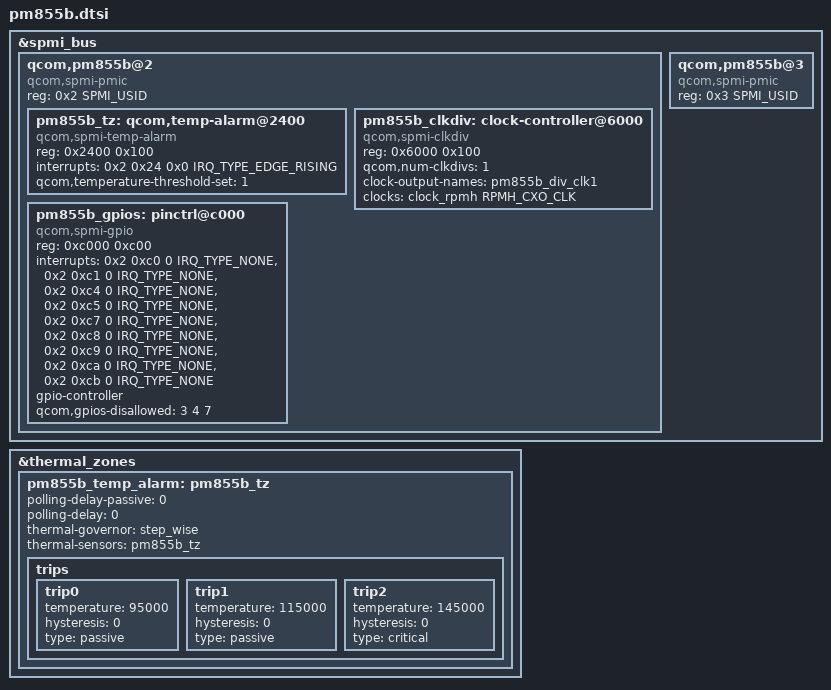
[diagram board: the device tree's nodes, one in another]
/*
 * Copyright (c) 2017-2018, The Linux Foundation. All rights reserved.
 *
 * This program is free software; you can redistribute it and/or modify
 * it under the terms of the GNU General Public License version 2 and
 * only version 2 as published by the Free Software Foundation.
 *
 * This program is distributed in the hope that it will be useful,
 * but WITHOUT ANY WARRANTY; without even the implied warranty of
 * MERCHANTABILITY or FITNESS FOR A PARTICULAR PURPOSE.  See the
 * GNU General Public License for more details.
 */

#include <dt-bindings/spmi/spmi.h>
#include <dt-bindings/interrupt-controller/irq.h>

&spmi_bus {
	qcom,pm855b@2 {
		compatible = "qcom,spmi-pmic";
		reg = <0x2 SPMI_USID>;
		#address-cells = <2>;
		#size-cells = <0>;

		pm855b_tz: qcom,temp-alarm@2400 {
			compatible = "qcom,spmi-temp-alarm";
			reg = <0x2400 0x100>;
			interrupts = <0x2 0x24 0x0 IRQ_TYPE_EDGE_RISING>;
			#thermal-sensor-cells = <0>;
			qcom,temperature-threshold-set = <1>;
		};

		pm855b_clkdiv: clock-controller@6000 {
			compatible = "qcom,spmi-clkdiv";
			reg = <0x6000 0x100>;
			#clock-cells = <1>;
			qcom,num-clkdivs = <1>;
			clock-output-names = "pm855b_div_clk1";
			clocks = <&clock_rpmh RPMH_CXO_CLK>;
			clock-names = "xo";
		};

		pm855b_gpios: pinctrl@c000 {
			compatible = "qcom,spmi-gpio";
			reg = <0xc000 0xc00>;
			interrupts = <0x2 0xc0 0 IRQ_TYPE_NONE>,
					<0x2 0xc1 0 IRQ_TYPE_NONE>,
					<0x2 0xc4 0 IRQ_TYPE_NONE>,
					<0x2 0xc5 0 IRQ_TYPE_NONE>,
					<0x2 0xc7 0 IRQ_TYPE_NONE>,
					<0x2 0xc8 0 IRQ_TYPE_NONE>,
					<0x2 0xc9 0 IRQ_TYPE_NONE>,
					<0x2 0xca 0 IRQ_TYPE_NONE>,
					<0x2 0xcb 0 IRQ_TYPE_NONE>;
			interrupt-names = "pm855b_gpio1", "pm855b_gpio2",
					"pm855b_gpio5", "pm855b_gpio6",
					"pm855b_gpio8", "pm855b_gpio9",
					"pm855b_gpio10", "pm855b_gpio11",
					"pm855b_gpio12";
			gpio-controller;
			#gpio-cells = <2>;
			qcom,gpios-disallowed = <3 4 7>;
		};
	};

	qcom,pm855b@3 {
		compatible ="qcom,spmi-pmic";
		reg = <0x3 SPMI_USID>;
		#address-cells = <2>;
		#size-cells = <0>;
	};
};

&thermal_zones {
	pm855b_temp_alarm: pm855b_tz {
		polling-delay-passive = <0>;
		polling-delay = <0>;
		thermal-governor = "step_wise";
		thermal-sensors = <&pm855b_tz>;

		trips {
			trip0 {
				temperature = <95000>;
				hysteresis = <0>;
				type = "passive";
			};
			trip1 {
				temperature = <115000>;
				hysteresis = <0>;
				type = "passive";
			};
			trip2 {
				temperature = <145000>;
				hysteresis = <0>;
				type = "critical";
			};
		};
	};
};
